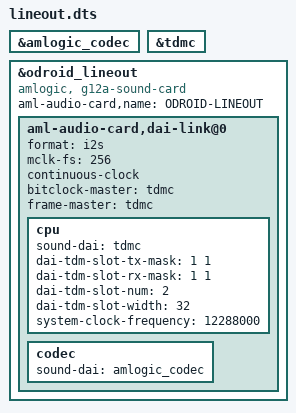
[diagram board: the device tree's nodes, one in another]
/dts-v1/;
/plugin/;

/ {
	fragment@0 {
		target = <&amlogic_codec>;
		__overlay__ {
			status = "okay";
		};
	};

	fragment@1 {
		target = <&tdmc>;
		__overlay__ {
			status = "okay";
		};
	};

	fragment@2 {
		target = <&odroid_lineout>;
		__overlay__ {
			compatible = "amlogic, g12a-sound-card";
			aml-audio-card,name = "ODROID-LINEOUT";
			status = "okay";

			/* ODROID-C4: Line-out(J4)*/
			aml-audio-card,dai-link@0 {
				format = "i2s";
				mclk-fs = <256>;
				continuous-clock;
				bitclock-master = <&tdmc>;
				frame-master = <&tdmc>;
				cpu {
					sound-dai = <&tdmc>;
					dai-tdm-slot-tx-mask = <1 1>;
					dai-tdm-slot-rx-mask = <1 1>;
					dai-tdm-slot-num = <2>;
					dai-tdm-slot-width = <32>;
					system-clock-frequency = <12288000>;
				};
				codec {
					sound-dai = <&amlogic_codec>;
				};
			};
		};
	};
};
